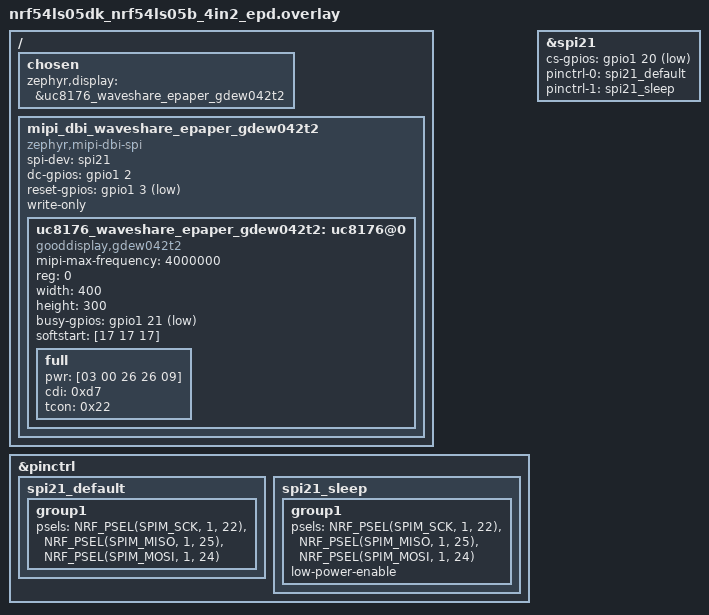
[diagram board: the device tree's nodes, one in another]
#include "nrf54ls05dk_nrf54ls05b_memory.dtsi"

/ {
	chosen {
		zephyr,display = &uc8176_waveshare_epaper_gdew042t2;
	};

	mipi_dbi_waveshare_epaper_gdew042t2 {
		compatible = "zephyr,mipi-dbi-spi";
		spi-dev = <&spi21>;
		dc-gpios = <&gpio1 2 GPIO_ACTIVE_HIGH>;
		reset-gpios = <&gpio1 3 GPIO_ACTIVE_LOW>;
		write-only;
		#address-cells = <1>;
		#size-cells = <0>;

		uc8176_waveshare_epaper_gdew042t2: uc8176@0 {
			compatible = "gooddisplay,gdew042t2", "ultrachip,uc8176";
			mipi-max-frequency = <4000000>;
			reg = <0>;
			width = <400>;
			height = <300>;
			busy-gpios = <&gpio1 21 GPIO_ACTIVE_LOW>;

			softstart = [17 17 17];

			full {
				pwr = [03 00 26 26 09];
				cdi = <0xd7>;
				tcon = <0x22>;
			};
		};
	};

};

&pinctrl {
	spi21_default: spi21_default {
		group1 {
			// nordic,drive-mode = <NRF_DRIVE_H0H1>;
			psels = <NRF_PSEL(SPIM_SCK, 1, 22)>,
			        <NRF_PSEL(SPIM_MISO, 1, 25)>,
			        <NRF_PSEL(SPIM_MOSI, 1, 24)>;
		};
	};

	spi21_sleep: spi21_sleep {
		group1 {
			psels = <NRF_PSEL(SPIM_SCK, 1, 22)>,
			        <NRF_PSEL(SPIM_MISO, 1, 25)>,
			        <NRF_PSEL(SPIM_MOSI, 1, 24)>;
			low-power-enable;
		};
	};

};

&spi21 {
	status = "okay";
	cs-gpios = <&gpio1 20 GPIO_ACTIVE_LOW>;
	pinctrl-0 = <&spi21_default>;
	pinctrl-1 = <&spi21_sleep>;
	pinctrl-names = "default", "sleep";
};
